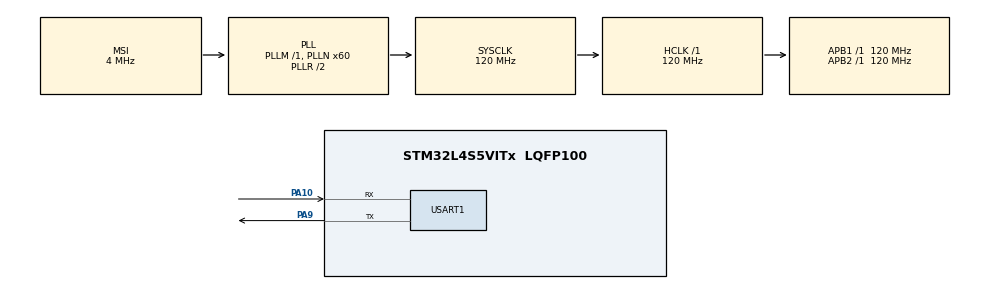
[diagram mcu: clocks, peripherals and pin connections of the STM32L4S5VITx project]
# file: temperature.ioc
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Mcu.Family=STM32L4
RCC.MSI_VALUE=4000000
RCC.CortexFreq_Value=120000000
ADC1.Rank-0\#ChannelRegularConversion=1
PA10.Mode=Asynchronous
VP_ADC1_TempSens_Input.Mode=IN-TempSens
ADC1.OffsetNumber-0\#ChannelRegularConversion=ADC_OFFSET_NONE
RCC.SYSCLKSource=RCC_SYSCLKSOURCE_PLLCLK
ProjectManager.StackSize=0x400
USART1.VirtualMode-Asynchronous=VM_ASYNC
PA9.Mode=Asynchronous
ProjectManager.TargetToolchain=STM32CubeIDE
RCC.HCLKFreq_Value=120000000
RCC.APB2TimFreq_Value=120000000
PA9.Signal=USART1_TX
RCC.USBFreq_Value=48000000
RCC.LSE_VALUE=32768
RCC.AHBFreq_Value=120000000
ADC1.Channel-0\#ChannelRegularConversion=ADC_CHANNEL_TEMPSENSOR
RCC.HSE_VALUE=8000000
board=B-L4S5I-IOT01A
RCC.VCOOutputFreq_Value=240000000
RCC.APB2Freq_Value=120000000
VP_TIM2_VS_ClockSourceINT.Mode=Internal
RCC.ADCFreq_Value=48000000
TIM2.Period=2000
Mcu.Name=STM32L4S5VITx
ADC1.SamplingTime-0\#ChannelRegularConversion=ADC_SAMPLETIME_2CYCLES_5
RCC.SYSCLKFreq_VALUE=120000000
Mcu.Package=LQFP100
TIM2.Prescaler=60000
ADC1.master=1
PA10.Signal=USART1_RX
ProjectManager.HeapSize=0x200
RCC.HSI_VALUE=16000000
NVIC.PriorityGroup=NVIC_PRIORITYGROUP_4
ADC1.NbrOfConversionFlag=1
RCC.PLLN=60
RCC.APB1TimFreq_Value=120000000
RCC.APB1Freq_Value=120000000
RCC.HSI48_VALUE=48000000
RCC.PLLSAI1N=24

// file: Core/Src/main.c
/* USER CODE BEGIN Header */
/**
  ******************************************************************************
  * @file           : main.c
  * @brief          : Main program body
  ******************************************************************************
  * @attention
  *
  * <h2><center>&copy; Copyright (c) 2021 STMicroelectronics.
  * All rights reserved.</center></h2>
  *
  * This software component is licensed by ST under BSD 3-Clause license,
  * the "License"; You may not use this file except in compliance with the
  * License. You may obtain a copy of the License at:
  *                        opensource.org/licenses/BSD-3-Clause
  *
  ******************************************************************************
  */
/* USER CODE END Header */
#include "main.h"

/* USER CODE BEGIN PTD */
#define TS_CAL1_Addr 0x1FFF75A8
#define TS_CAL1 ((uint16_t*)TS_CAL1_Addr)
#define TS_CAL2_Addr 0x1FFF75CA
#define TS_CAL2 ((uint16_t*)TS_CAL2_Addr)
/* USER CODE END PTD */

ADC_HandleTypeDef hadc1;

TIM_HandleTypeDef htim2;

UART_HandleTypeDef huart1;

void SystemClock_Config(void);
static void MX_GPIO_Init(void);
static void MX_ADC1_Init(void);
static void MX_TIM2_Init(void);
static void MX_USART1_UART_Init(void);

int main(void)
{

  /* MCU Configuration--------------------------------------------------------*/

  /* Reset of all peripherals, Initializes the Flash interface and the Systick. */
  HAL_Init();

  /* Configure the system clock */
  SystemClock_Config();

  /* Initialize all configured peripherals */
  MX_GPIO_Init();
  MX_ADC1_Init();
  MX_TIM2_Init();
  MX_USART1_UART_Init();
  /* USER CODE BEGIN 2 */

  HAL_ADC_Start(&hadc1);
  HAL_ADC_PollForConversion(&hadc1, 1000);
  uint16_t raw = HAL_ADC_GetValue(&hadc1); //ADC is a 12bit value, uint12_t, though 16 bit int shouldnt be problem

  uint16_t cal1 = *(uint16_t*)TS_CAL1_Addr;
  uint16_t cal2 = *(uint16_t*)TS_CAL2_Addr;

  uint32_t temperature = (raw - cal1) * ((130 - 30) / (cal2 - cal1)) + 30; // should be adc/reference, multiplication by 3000 not needed, check this
  /* USER CODE END 2 */

  /* Infinite loop */
  while (1)
  {

  }
}

void SystemClock_Config(void)
{
  RCC_OscInitTypeDef RCC_OscInitStruct = {0};
  RCC_ClkInitTypeDef RCC_ClkInitStruct = {0};
  RCC_PeriphCLKInitTypeDef PeriphClkInit = {0};

  /** Configure the main internal regulator output voltage
  */
  if (HAL_PWREx_ControlVoltageScaling(PWR_REGULATOR_VOLTAGE_SCALE1_BOOST) != HAL_OK)
  {
    Error_Handler();
  }
  /** Initializes the RCC Oscillators according to the specified parameters
  * in the RCC_OscInitTypeDef structure.
  */
  RCC_OscInitStruct.OscillatorType = RCC_OSCILLATORTYPE_MSI;
  RCC_OscInitStruct.MSIState = RCC_MSI_ON;
  RCC_OscInitStruct.MSICalibrationValue = 0;
  RCC_OscInitStruct.MSIClockRange = RCC_MSIRANGE_6;
  RCC_OscInitStruct.PLL.PLLState = RCC_PLL_ON;
  RCC_OscInitStruct.PLL.PLLSource = RCC_PLLSOURCE_MSI;
  RCC_OscInitStruct.PLL.PLLM = 1;
  RCC_OscInitStruct.PLL.PLLN = 60;
  RCC_OscInitStruct.PLL.PLLP = RCC_PLLP_DIV2;
  RCC_OscInitStruct.PLL.PLLQ = RCC_PLLQ_DIV2;
  RCC_OscInitStruct.PLL.PLLR = RCC_PLLR_DIV2;
  if (HAL_RCC_OscConfig(&RCC_OscInitStruct) != HAL_OK)
  {
    Error_Handler();
  }
  /** Initializes the CPU, AHB and APB buses clocks
  */
  RCC_ClkInitStruct.ClockType = RCC_CLOCKTYPE_HCLK|RCC_CLOCKTYPE_SYSCLK
                              |RCC_CLOCKTYPE_PCLK1|RCC_CLOCKTYPE_PCLK2;
  RCC_ClkInitStruct.SYSCLKSource = RCC_SYSCLKSOURCE_PLLCLK;
  RCC_ClkInitStruct.AHBCLKDivider = RCC_SYSCLK_DIV1;
  RCC_ClkInitStruct.APB1CLKDivider = RCC_HCLK_DIV1;
  RCC_ClkInitStruct.APB2CLKDivider = RCC_HCLK_DIV1;

  if (HAL_RCC_ClockConfig(&RCC_ClkInitStruct, FLASH_LATENCY_5) != HAL_OK)
  {
    Error_Handler();
  }
  PeriphClkInit.PeriphClockSelection = RCC_PERIPHCLK_USART1|RCC_PERIPHCLK_ADC;
  PeriphClkInit.Usart1ClockSelection = RCC_USART1CLKSOURCE_PCLK2;
  PeriphClkInit.AdcClockSelection = RCC_ADCCLKSOURCE_PLLSAI1;
  PeriphClkInit.PLLSAI1.PLLSAI1Source = RCC_PLLSOURCE_MSI;
  PeriphClkInit.PLLSAI1.PLLSAI1M = 1;
  PeriphClkInit.PLLSAI1.PLLSAI1N = 24;
  PeriphClkInit.PLLSAI1.PLLSAI1P = RCC_PLLP_DIV2;
  PeriphClkInit.PLLSAI1.PLLSAI1Q = RCC_PLLQ_DIV2;
  PeriphClkInit.PLLSAI1.PLLSAI1R = RCC_PLLR_DIV2;
  PeriphClkInit.PLLSAI1.PLLSAI1ClockOut = RCC_PLLSAI1_ADC1CLK;
  if (HAL_RCCEx_PeriphCLKConfig(&PeriphClkInit) != HAL_OK)
  {
    Error_Handler();
  }
}

static void MX_ADC1_Init(void)
{

  ADC_ChannelConfTypeDef sConfig = {0};

  /** Common config
  */
  hadc1.Instance = ADC1;
  hadc1.Init.ClockPrescaler = ADC_CLOCK_ASYNC_DIV1;
  hadc1.Init.Resolution = ADC_RESOLUTION_12B;
  hadc1.Init.DataAlign = ADC_DATAALIGN_RIGHT;
  hadc1.Init.ScanConvMode = ADC_SCAN_DISABLE;
  hadc1.Init.EOCSelection = ADC_EOC_SINGLE_CONV;
  hadc1.Init.LowPowerAutoWait = DISABLE;
  hadc1.Init.ContinuousConvMode = DISABLE;
  hadc1.Init.NbrOfConversion = 1;
  hadc1.Init.DiscontinuousConvMode = DISABLE;
  hadc1.Init.ExternalTrigConv = ADC_SOFTWARE_START;
  hadc1.Init.ExternalTrigConvEdge = ADC_EXTERNALTRIGCONVEDGE_NONE;
  hadc1.Init.DMAContinuousRequests = DISABLE;
  hadc1.Init.Overrun = ADC_OVR_DATA_PRESERVED;
  hadc1.Init.OversamplingMode = DISABLE;
  if (HAL_ADC_Init(&hadc1) != HAL_OK)
  {
    Error_Handler();
  }
  /** Configure Regular Channel
  */
  sConfig.Channel = ADC_CHANNEL_TEMPSENSOR;
  sConfig.Rank = ADC_REGULAR_RANK_1;
  sConfig.SamplingTime = ADC_SAMPLETIME_2CYCLES_5;
  sConfig.SingleDiff = ADC_SINGLE_ENDED;
  sConfig.OffsetNumber = ADC_OFFSET_NONE;
  sConfig.Offset = 0;
  if (HAL_ADC_ConfigChannel(&hadc1, &sConfig) != HAL_OK)
  {
    Error_Handler();
  }

}

static void MX_TIM2_Init(void)
{

  TIM_ClockConfigTypeDef sClockSourceConfig = {0};
  TIM_MasterConfigTypeDef sMasterConfig = {0};

  htim2.Instance = TIM2;
  htim2.Init.Prescaler = 60000;
  htim2.Init.CounterMode = TIM_COUNTERMODE_UP;
  htim2.Init.Period = 2000;
  htim2.Init.ClockDivision = TIM_CLOCKDIVISION_DIV1;
  htim2.Init.AutoReloadPreload = TIM_AUTORELOAD_PRELOAD_DISABLE;
  if (HAL_TIM_Base_Init(&htim2) != HAL_OK)
  {
    Error_Handler();
  }
  sClockSourceConfig.ClockSource = TIM_CLOCKSOURCE_INTERNAL;
  if (HAL_TIM_ConfigClockSource(&htim2, &sClockSourceConfig) != HAL_OK)
  {
    Error_Handler();
  }
  sMasterConfig.MasterOutputTrigger = TIM_TRGO_RESET;
  sMasterConfig.MasterSlaveMode = TIM_MASTERSLAVEMODE_DISABLE;
  if (HAL_TIMEx_MasterConfigSynchronization(&htim2, &sMasterConfig) != HAL_OK)
  {
    Error_Handler();
  }

}

static void MX_USART1_UART_Init(void)
{

  huart1.Instance = USART1;
  huart1.Init.BaudRate = 115200;
  huart1.Init.WordLength = UART_WORDLENGTH_8B;
  huart1.Init.StopBits = UART_STOPBITS_1;
  huart1.Init.Parity = UART_PARITY_NONE;
  huart1.Init.Mode = UART_MODE_TX_RX;
  huart1.Init.HwFlowCtl = UART_HWCONTROL_NONE;
  huart1.Init.OverSampling = UART_OVERSAMPLING_16;
  huart1.Init.OneBitSampling = UART_ONE_BIT_SAMPLE_DISABLE;
  huart1.Init.ClockPrescaler = UART_PRESCALER_DIV1;
  huart1.AdvancedInit.AdvFeatureInit = UART_ADVFEATURE_NO_INIT;
  if (HAL_UART_Init(&huart1) != HAL_OK)
  {
    Error_Handler();
  }
  if (HAL_UARTEx_SetTxFifoThreshold(&huart1, UART_TXFIFO_THRESHOLD_1_8) != HAL_OK)
  {
    Error_Handler();
  }
  if (HAL_UARTEx_SetRxFifoThreshold(&huart1, UART_RXFIFO_THRESHOLD_1_8) != HAL_OK)
  {
    Error_Handler();
  }
  if (HAL_UARTEx_DisableFifoMode(&huart1) != HAL_OK)
  {
    Error_Handler();
  }

}

static void MX_GPIO_Init(void)
{

  /* GPIO Ports Clock Enable */
  __HAL_RCC_GPIOA_CLK_ENABLE();

}

void Error_Handler(void)
{
  __disable_irq();
  while (1)
  {
  }
}

/************************ (C) COPYRIGHT STMicroelectronics *****END OF FILE****/
